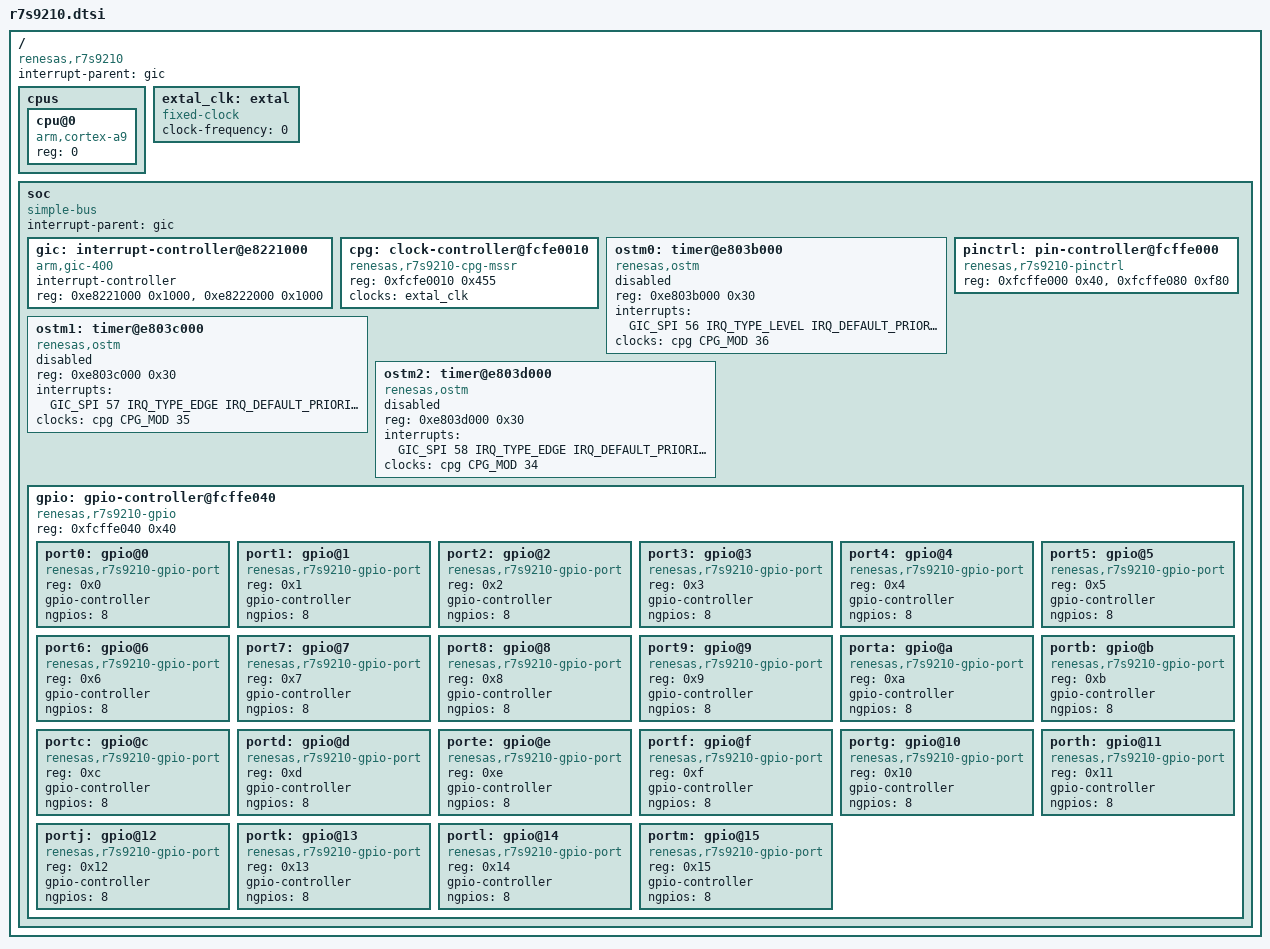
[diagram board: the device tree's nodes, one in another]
/*
 * Copyright (c) 2023 EPAM Systems
 *
 * SPDX-License-Identifier: Apache-2.0
 */

#include <mem.h>
#include <arm/armv7-a.dtsi>
#include <zephyr/dt-bindings/interrupt-controller/arm-gic.h>
#include <zephyr/dt-bindings/clock/renesas_cpg_mssr.h>
#include <zephyr/dt-bindings/clock/r7s9210_cpg_mssr.h>

/ {
	compatible = "renesas,r7s9210";
	interrupt-parent = <&gic>;
	#address-cells = <1>;
	#size-cells = <1>;

	cpus {
		#address-cells = <1>;
		#size-cells = <0>;

		cpu@0 {
			device_type = "cpu";
			compatible = "arm,cortex-a9";
			reg = <0>;
		};
	};

	extal_clk: extal {
		#clock-cells = <0>;
		compatible = "fixed-clock";
		/* Value must be set by board */
		clock-frequency = <0>;
	};

	soc {
		compatible = "simple-bus";
		interrupt-parent = <&gic>;

		#address-cells = <1>;
		#size-cells = <1>;
		ranges;

		gic: interrupt-controller@e8221000 {
			compatible = "arm,gic-400", "arm,gic-v2", "arm,gic";
			#interrupt-cells = <4>;
			#address-cells = <0>;
			interrupt-controller;
			reg = <0xe8221000 0x1000>,
			      <0xe8222000 0x1000>;
		};

		cpg: clock-controller@fcfe0010 {
			compatible = "renesas,r7s9210-cpg-mssr";
			reg = <0xfcfe0010 0x455>;
			#clock-cells = <2>;
			clocks = <&extal_clk>;
		};

		/* By default, this timer can only be accessed from security mode. If you wish to
		 * enable access to it from non-secure mode, you will need to modify the SLVACCCTL1
		 * AXI register.
		 * See, RZ/A2M Group User’s Manual: Hardware (R01UH0746EJ0400 Rev.4.00)
		 * 5.11.26 Slave Access Control Register 1 (SLVACCCTL1)
		 */
		ostm0: timer@e803b000 {
			compatible = "renesas,ostm";
			reg = <0xe803b000 0x30>;
			interrupts = <GIC_SPI 56 IRQ_TYPE_LEVEL IRQ_DEFAULT_PRIORITY>;
			clocks = <&cpg CPG_MOD 36>;
			status = "disabled";
		};

		ostm1: timer@e803c000 {
			compatible = "renesas,ostm";
			reg = <0xe803c000 0x30>;
			interrupts = <GIC_SPI 57 IRQ_TYPE_EDGE IRQ_DEFAULT_PRIORITY>;
			clocks = <&cpg CPG_MOD 35>;
			status = "disabled";
		};

		ostm2: timer@e803d000 {
			compatible = "renesas,ostm";
			reg = <0xe803d000 0x30>;
			interrupts = <GIC_SPI 58 IRQ_TYPE_EDGE IRQ_DEFAULT_PRIORITY>;
			clocks = <&cpg CPG_MOD 34>;
			status = "disabled";
		};

		pinctrl: pin-controller@fcffe000 {
			compatible = "renesas,r7s9210-pinctrl";
			reg = <0xfcffe000 0x40>, <0xfcffe080 0xf80>;
			reg-names = "pdr", "pinctrl";
		};

		gpio: gpio-controller@fcffe040{
			compatible = "renesas,r7s9210-gpio";
			reg = <0xfcffe040 0x40>;
			#address-cells = <1>;
			#size-cells = <0>;

			port0: gpio@0 {
				compatible = "renesas,r7s9210-gpio-port";
				reg = <0x0>; /* PORT0 */
				gpio-controller;
				#gpio-cells=<2>;
				ngpios = <8>;
			};

			port1: gpio@1 {
				compatible = "renesas,r7s9210-gpio-port";
				reg = <0x1>; /* PORT1 */
				gpio-controller;
				#gpio-cells=<2>;
				ngpios = <8>;
			};
			port2: gpio@2 {
				compatible = "renesas,r7s9210-gpio-port";
				reg = <0x2>; /* PORT2 */
				gpio-controller;
				#gpio-cells=<2>;
				ngpios = <8>;
			};
			port3: gpio@3 {
				compatible = "renesas,r7s9210-gpio-port";
				reg = <0x3>; /* PORT3 */
				gpio-controller;
				#gpio-cells=<2>;
				ngpios = <8>;
			};
			port4: gpio@4 {
				compatible = "renesas,r7s9210-gpio-port";
				reg = <0x4>; /* PORT4 */
				gpio-controller;
				#gpio-cells=<2>;
				ngpios = <8>;
			};
			port5: gpio@5 {
				compatible = "renesas,r7s9210-gpio-port";
				reg = <0x5>; /* PORT5 */
				gpio-controller;
				#gpio-cells=<2>;
				ngpios = <8>;
			};
			port6: gpio@6 {
				compatible = "renesas,r7s9210-gpio-port";
				reg = <0x6>; /* PORT6 */
				gpio-controller;
				#gpio-cells=<2>;
				ngpios = <8>;
			};
			port7: gpio@7 {
				compatible = "renesas,r7s9210-gpio-port";
				reg = <0x7>; /* PORT7 */
				gpio-controller;
				#gpio-cells=<2>;
				ngpios = <8>;
			};
			port8: gpio@8 {
				compatible = "renesas,r7s9210-gpio-port";
				reg = <0x8>; /* PORT8 */
				gpio-controller;
				#gpio-cells=<2>;
				ngpios = <8>;
			};
			port9: gpio@9 {
				compatible = "renesas,r7s9210-gpio-port";
				reg = <0x9>; /* PORT9 */
				gpio-controller;
				#gpio-cells=<2>;
				ngpios = <8>;
			};
			porta: gpio@a {
				compatible = "renesas,r7s9210-gpio-port";
				reg = <0xa>; /* PORTA */
				gpio-controller;
				#gpio-cells=<2>;
				ngpios = <8>;
			};
			portb: gpio@b {
				compatible = "renesas,r7s9210-gpio-port";
				reg = <0xb>; /* PORTB */
				gpio-controller;
				#gpio-cells=<2>;
				ngpios = <8>;
			};
			portc: gpio@c {
				compatible = "renesas,r7s9210-gpio-port";
				reg = <0xc>; /* PORTC */
				gpio-controller;
				#gpio-cells=<2>;
				ngpios = <8>;
			};
			portd: gpio@d {
				compatible = "renesas,r7s9210-gpio-port";
				reg = <0xd>; /* PORTD */
				gpio-controller;
				#gpio-cells=<2>;
				ngpios = <8>;
			};
			porte: gpio@e {
				compatible = "renesas,r7s9210-gpio-port";
				reg = <0xe>; /* PORTE */
				gpio-controller;
				#gpio-cells=<2>;
				ngpios = <8>;
			};
			portf: gpio@f {
				compatible = "renesas,r7s9210-gpio-port";
				reg = <0xf>; /* PORTF */
				gpio-controller;
				#gpio-cells=<2>;
				ngpios = <8>;
			};
			portg: gpio@10 {
				compatible = "renesas,r7s9210-gpio-port";
				reg = <0x10>; /* PORTG */
				gpio-controller;
				#gpio-cells=<2>;
				ngpios = <8>;
			};
			porth: gpio@11 {
				compatible = "renesas,r7s9210-gpio-port";
				reg = <0x11>; /* PORTH */
				gpio-controller;
				#gpio-cells=<2>;
				ngpios = <8>;
			};
			portj: gpio@12 {
				compatible = "renesas,r7s9210-gpio-port";
				reg = <0x12>; /* PORTJ */
				gpio-controller;
				#gpio-cells=<2>;
				ngpios = <8>;
			};
			portk: gpio@13 {
				compatible = "renesas,r7s9210-gpio-port";
				reg = <0x13>; /* PORTK */
				gpio-controller;
				#gpio-cells=<2>;
				ngpios = <8>;
			};
			portl: gpio@14 {
				compatible = "renesas,r7s9210-gpio-port";
				reg = <0x14>; /* PORTL */
				gpio-controller;
				#gpio-cells=<2>;
				ngpios = <8>;
			};
			portm: gpio@15 {
				compatible = "renesas,r7s9210-gpio-port";
				reg = <0x15>; /* PORTM */
				gpio-controller;
				#gpio-cells=<2>;
				ngpios = <8>;
			};
		};
	};
};
